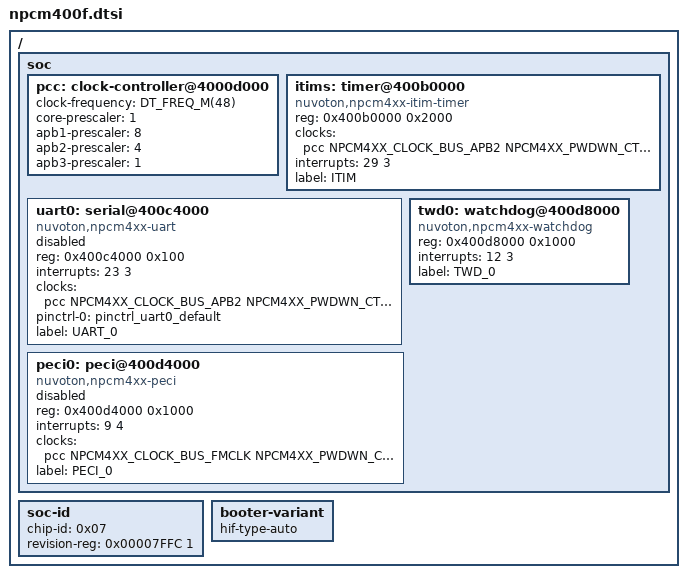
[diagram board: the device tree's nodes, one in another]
/*
 * Copyright (c) 2021 Nuvoton Technology Corporation.
 *
 * SPDX-License-Identifier: Apache-2.0
 */


/* Device tree declarations of npcm4xx soc family */
#include "npcm4xx.dtsi"
#include "npcm4xx/npcm4xx-pinctrl.dtsi"

/ {
	soc {

		pcc: clock-controller@4000d000 {
			clock-frequency = <DT_FREQ_M(48)>; /* OFMCLK runs at 48MHz */
			core-prescaler = <1>; /* CORE_CLK runs at 48MHz */
			apb1-prescaler = <8>; /* APB1_CLK runs at 6MHz */
			apb2-prescaler = <4>; /* APB2_CLK runs at 12MHz */
			apb3-prescaler = <1>; /* APB3_CLK runs at 48MHz */
		};

		/* Specific soc devices in npcm400f series */
		itims: timer@400b0000 {
			compatible = "nuvoton,npcm4xx-itim-timer";
			reg = <0x400b0000 0x2000>;
			reg-names = "itim1";
			clocks = <&pcc NPCM4XX_CLOCK_BUS_APB2 NPCM4XX_PWDWN_CTL4 0>;
			interrupts = <29 3>;
			label = "ITIM";
		};

		uart0: serial@400c4000 {
			compatible = "nuvoton,npcm4xx-uart";
			reg = <0x400c4000 0x100>;
			interrupts = <23 3>;
			clocks = <&pcc NPCM4XX_CLOCK_BUS_APB2 NPCM4XX_PWDWN_CTL1 4>;
			pinctrl-0 = <&pinctrl_uart0_default>;
			/* uart-rx = <&wui_cr_sin1>;*/
			status = "disabled";
			label = "UART_0";
		};

		twd0: watchdog@400d8000 {
			compatible = "nuvoton,npcm4xx-watchdog";
			reg = <0x400d8000 0x1000>;
			interrupts = <12 3>;
			label = "TWD_0";
		};

		peci0: peci@400d4000 {
			compatible = "nuvoton,npcm4xx-peci";
			reg = <0x400d4000 0x1000>;
			#address-cells = <1>;
			#size-cells = <0>;
			interrupts = <9 4>;
			clocks = <&pcc NPCM4XX_CLOCK_BUS_FMCLK NPCM4XX_PWDWN_CTL4 5>;
			label = "PECI_0";
			status = "disabled";
		};
	};

	soc-id {
		chip-id = <0x07>;
		revision-reg = <0x00007FFC 1>;
	};

	booter-variant {
		hif-type-auto;
	};
};
